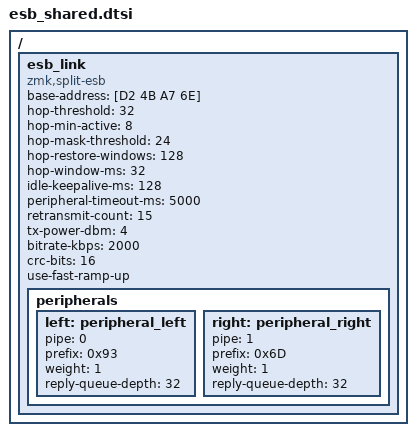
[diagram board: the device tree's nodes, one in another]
/ {
    esb_link {
        compatible = "zmk,split-esb";
        base-address = [D2 4B A7 6E];

        hop-threshold = <32>;
        hop-min-active = <8>;
        hop-mask-threshold = <24>;
        hop-restore-windows = <128>;

        hop-window-ms = <32>;
        idle-keepalive-ms = <128>;
        peripheral-timeout-ms = <5000>;

        retransmit-count = <15>;

        tx-power-dbm = <4>;
        bitrate-kbps = <2000>;
        crc-bits = <16>;
        use-fast-ramp-up;

        peripherals {
            left: peripheral_left {
                pipe = <0>;
                prefix = <0x93>;
                weight = <1>;
                reply-queue-depth = <32>;
            };
            right: peripheral_right {
                pipe = <1>;
                prefix = <0x6D>;
                weight = <1>;
                reply-queue-depth = <32>;
            };
        };
    };
};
